# STM32F217xx register map
File version: 1.0
Registers are 32-bit, read-write, reset 0x0 unless marked. A register's access mark holds for its fields unless they carry their own. Offsets are from the block's base; [hi:lo] are bit positions; {n}, {i} and the like mark numbered series; 'fields as' and 'values as' point back to an identical list.

## RCC — Reset and Clock Control
Base 0x40023800
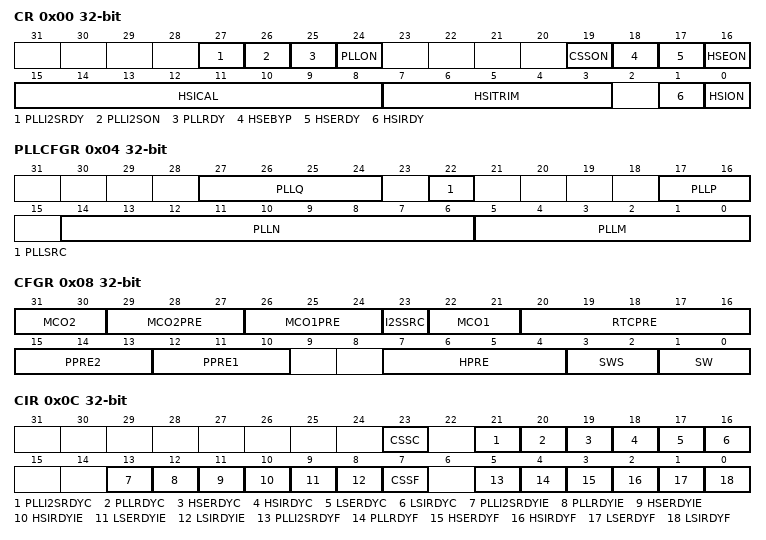
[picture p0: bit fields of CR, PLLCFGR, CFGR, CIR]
0x00 CR — RCC clock control register
  [27] PLLI2SRDY, [26] PLLI2SON, [25] PLLRDY, [24] PLLON, [19] CSSON, [18] HSEBYP, [17] HSERDY, [16] HSEON, [15:8] HSICAL, [7:3] HSITRIM, [1] HSIRDY, [0] HSION
0x04 PLLCFGR — RCC PLL configuration register
  [27:24] PLLQ
    {v}=DIV_{v} (Main PLL division factor for PLLQ output by {v}) (v=2..15)
  [22] PLLSRC
    0=HSI (HSI16 clock selected as PLL entry clock source); 1=HSE (HSE clock selected as PLL entry clock source)
  [17:16] PLLP
    0=DIV_2 (Main PLL division factor for PLLP output by 2); 1=DIV_4 (Main PLL division factor for PLLP output by 4); 2=DIV_6 (Main PLL division factor for PLLP output by 6); 3=DIV_8 (Main PLL division factor for PLLP output by 8)
  [14:6] PLLN
  [5:0] PLLM
    {v}=DIV_{v} (PLL and PLLI2S division factor by {v}) (v=2..63)
0x08 CFGR — RCC clock configuration register
  [31:30] MCO2
  [29:27] MCO2PRE
  [26:24] MCO1PRE
  [23] I2SSRC
    0=PLLI2S (I2S oscillator clock used as I2S1 clock); 1=PIN (External pin clock used as I2S1 clock)
  [22:21] MCO1
  [20:16] RTCPRE
    0=NOCLOCK (HSE not divided); {v}=HSE_DIV_{v} (HSE clock divided by {v}) (v=2..31)
  [15:13] PPRE2 — PRE2[2:0] bits (APB2 prescaler)
    0=DIV_1 (HCLK not divided); 4=DIV_2 (HCLK divided by 2); 5=DIV_4 (HCLK divided by 4); 6=DIV_8 (HCLK divided by 8); 7=DIV_16 (HCLK divided by 16)
  [12:10] PPRE1 — PRE1[2:0] bits (APB1 prescaler)
    values as PPRE2
  [7:4] HPRE — HPRE[3:0] bits (AHB prescaler)
    0=DIV_1 (SYSCLK not divided); 8=DIV_2 (SYSCLK divided by 2); 9=DIV_4 (SYSCLK divided by 4); 10=DIV_8 (SYSCLK divided by 8); 11=DIV_16 (SYSCLK divided by 16); 12=DIV_64 (SYSCLK divided by 64); 13=DIV_128 (SYSCLK divided by 128); 14=DIV_256 (SYSCLK divided by 256); 15=DIV_512 (SYSCLK divided by 512)
  [3:2] SWS — SWS[1:0] bits (System Clock Switch Status)
    0=HSI (HSI used as system clock); 1=HSE (HSE used as system clock); 2=PLL (PLL used as system clock)
  [1:0] SW — SW[1:0] bits (System clock Switch)
    0=HSI (HSI selection as system clock); 1=HSE (HSE selection as system clock); 2=PLL (PLL selection as system clock)
0x0C CIR — RCC clock interrupt register
  [23] CSSC, [21] PLLI2SRDYC, [20] PLLRDYC, [19] HSERDYC, [18] HSIRDYC, [17] LSERDYC, [16] LSIRDYC, [13] PLLI2SRDYIE, [12] PLLRDYIE, [11] HSERDYIE, [10] HSIRDYIE, [9] LSERDYIE, [8] LSIRDYIE, [7] CSSF, [5] PLLI2SRDYF, [4] PLLRDYF, [3] HSERDYF, [2] HSIRDYF, [1] LSERDYF, [0] LSIRDYF
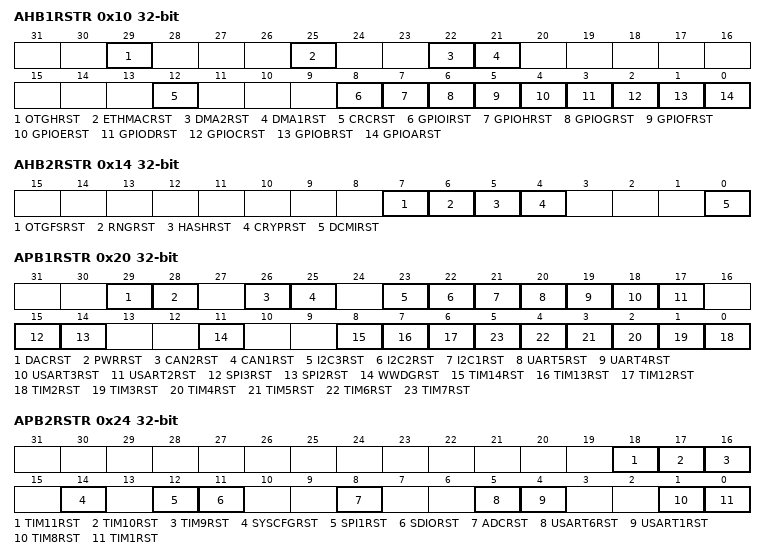
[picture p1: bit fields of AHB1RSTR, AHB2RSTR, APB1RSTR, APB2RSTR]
0x10 AHB1RSTR — RCC AHB1 peripheral reset register
  [29] OTGHRST, [25] ETHMACRST, [22] DMA2RST, [21] DMA1RST, [12] CRCRST, [8] GPIOIRST, [7] GPIOHRST, [6] GPIOGRST, [5] GPIOFRST, [4] GPIOERST, [3] GPIODRST, [2] GPIOCRST, [1] GPIOBRST, [0] GPIOARST
0x14 AHB2RSTR — RCC AHB2 peripheral reset register
  [7] OTGFSRST, [6] RNGRST, [5] HASHRST, [4] CRYPRST, [0] DCMIRST
0x18 AHB3RSTR — RCC AHB3 peripheral reset register
  [0] FSMCRST
0x20 APB1RSTR — RCC APB1 peripheral reset register
  [29] DACRST, [28] PWRRST, [26] CAN2RST, [25] CAN1RST, [23] I2C3RST, [22] I2C2RST, [21] I2C1RST, [20] UART5RST, [19] UART4RST, [18] USART3RST, [17] USART2RST, [15] SPI3RST, [14] SPI2RST, [11] WWDGRST, [8] TIM14RST, [7] TIM13RST, [6] TIM12RST, [n-2] TIM{n}RST (n=2..7)
0x24 APB2RSTR — RCC APB2 peripheral reset register
  [18] TIM11RST, [17] TIM10RST, [16] TIM9RST, [14] SYSCFGRST, [12] SPI1RST, [11] SDIORST, [8] ADCRST, [5] USART6RST, [4] USART1RST, [1] TIM8RST, [0] TIM1RST
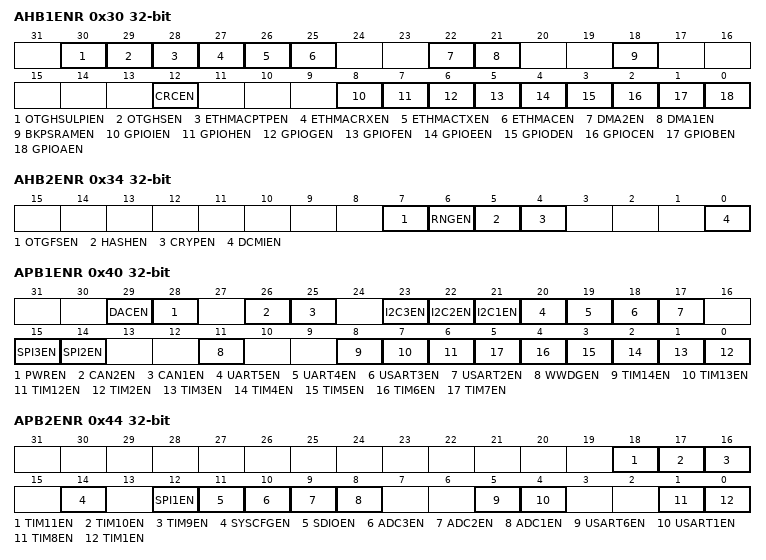
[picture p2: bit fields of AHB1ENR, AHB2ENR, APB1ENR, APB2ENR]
0x30 AHB1ENR — RCC AHB1 peripheral clock register
  [30] OTGHSULPIEN, [29] OTGHSEN, [28] ETHMACPTPEN, [27] ETHMACRXEN, [26] ETHMACTXEN, [25] ETHMACEN, [22] DMA2EN, [21] DMA1EN, [18] BKPSRAMEN, [12] CRCEN, [8] GPIOIEN, [7] GPIOHEN, [6] GPIOGEN, [5] GPIOFEN, [4] GPIOEEN, [3] GPIODEN, [2] GPIOCEN, [1] GPIOBEN, [0] GPIOAEN
0x34 AHB2ENR — RCC AHB2 peripheral clock register
  [7] OTGFSEN, [6] RNGEN, [5] HASHEN, [4] CRYPEN, [0] DCMIEN
0x38 AHB3ENR — RCC AHB3 peripheral clock register
  [0] FSMCEN
0x40 APB1ENR — RCC APB1 peripheral clock enable register
  [29] DACEN, [28] PWREN, [26] CAN2EN, [25] CAN1EN, [23] I2C3EN, [22] I2C2EN, [21] I2C1EN, [20] UART5EN, [19] UART4EN, [18] USART3EN, [17] USART2EN, [15] SPI3EN, [14] SPI2EN, [11] WWDGEN, [8] TIM14EN, [7] TIM13EN, [6] TIM12EN, [n-2] TIM{n}EN (n=2..7)
0x44 APB2ENR — RCC APB2 peripheral clock enable register
  [18] TIM11EN, [17] TIM10EN, [16] TIM9EN, [14] SYSCFGEN, [12] SPI1EN, [11] SDIOEN, [10] ADC3EN, [9] ADC2EN, [8] ADC1EN, [5] USART6EN, [4] USART1EN, [1] TIM8EN, [0] TIM1EN
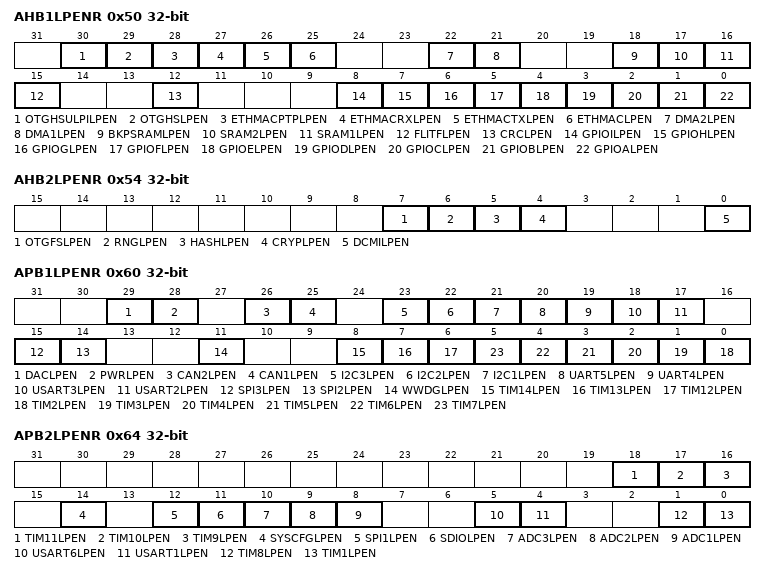
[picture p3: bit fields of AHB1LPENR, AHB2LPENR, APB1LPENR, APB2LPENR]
0x50 AHB1LPENR — RCC AHB1 peripheral clock enable in low power mode register
  [30] OTGHSULPILPEN, [29] OTGHSLPEN, [28] ETHMACPTPLPEN, [27] ETHMACRXLPEN, [26] ETHMACTXLPEN, [25] ETHMACLPEN, [22] DMA2LPEN, [21] DMA1LPEN, [18] BKPSRAMLPEN, [17] SRAM2LPEN, [16] SRAM1LPEN, [15] FLITFLPEN, [12] CRCLPEN, [8] GPIOILPEN, [7] GPIOHLPEN, [6] GPIOGLPEN, [5] GPIOFLPEN, [4] GPIOELPEN, [3] GPIODLPEN, [2] GPIOCLPEN, [1] GPIOBLPEN, [0] GPIOALPEN
0x54 AHB2LPENR — RCC AHB2 peripheral clock enable in low power mode register
  [7] OTGFSLPEN, [6] RNGLPEN, [5] HASHLPEN, [4] CRYPLPEN, [0] DCMILPEN
0x58 AHB3LPENR — RCC AHB3 peripheral clock enable in low power mode register
  [0] FSMCLPEN
0x60 APB1LPENR — RCC APB1 peripheral clock enable in low power mode register
  [29] DACLPEN, [28] PWRLPEN, [26] CAN2LPEN, [25] CAN1LPEN, [23] I2C3LPEN, [22] I2C2LPEN, [21] I2C1LPEN, [20] UART5LPEN, [19] UART4LPEN, [18] USART3LPEN, [17] USART2LPEN, [15] SPI3LPEN, [14] SPI2LPEN, [11] WWDGLPEN, [8] TIM14LPEN, [7] TIM13LPEN, [6] TIM12LPEN, [n-2] TIM{n}LPEN (n=2..7)
0x64 APB2LPENR — RCC APB2 peripheral clock enable in low power mode register
  [18] TIM11LPEN, [17] TIM10LPEN, [16] TIM9LPEN, [14] SYSCFGLPEN, [12] SPI1LPEN, [11] SDIOLPEN, [10] ADC3LPEN, [9] ADC2LPEN, [8] ADC1LPEN, [5] USART6LPEN, [4] USART1LPEN, [1] TIM8LPEN, [0] TIM1LPEN
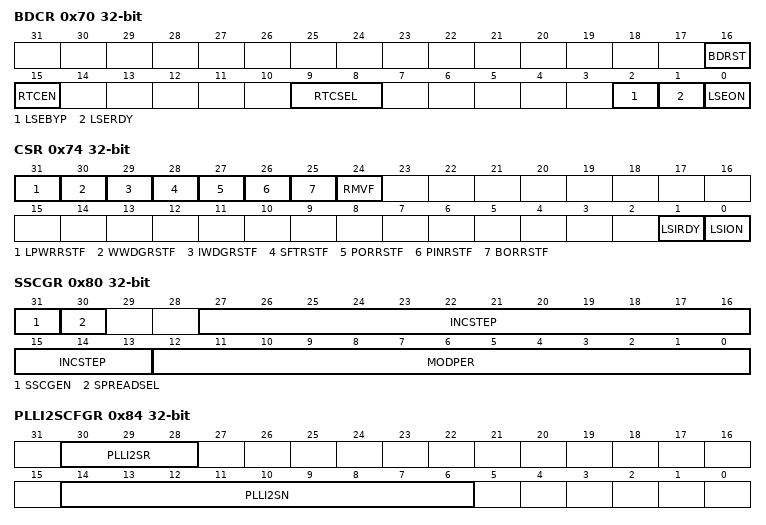
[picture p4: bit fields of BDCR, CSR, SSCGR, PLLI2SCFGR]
0x70 BDCR — RCC Backup domain control register
  [16] BDRST
  [15] RTCEN
  [9:8] RTCSEL
    0=NONE (No clock used as RTC clock); 1=LSE (LSE oscillator clock used as RTC clock); 2=LSI (LSI oscillator clock used as RTC clock); 3=HSE (HSE oscillator clock divided by HSE prescaler used as RTC clock)
  [2] LSEBYP
  [1] LSERDY
  [0] LSEON
0x74 CSR — RCC clock control & status register
  [31] LPWRRSTF, [30] WWDGRSTF, [29] IWDGRSTF, [28] SFTRSTF, [27] PORRSTF, [26] PINRSTF, [25] BORRSTF, [24] RMVF, [1] LSIRDY, [0] LSION
0x80 SSCGR — RCC spread spectrum clock generation register
  [31] SSCGEN
  [30] SPREADSEL
    0=CENTER (PLL center spread spectrum selection); 1=DOWN (PLL down spread spectrum selection)
  [27:13] INCSTEP
  [12:0] MODPER
0x84 PLLI2SCFGR — RCC PLLI2S configuration register
  [30:28] PLLI2SR
    {v}=DIV_{v} (PLLI2S division factor for PLLI2SR output by {v}) (v=2..7)
  [14:6] PLLI2SN
